# DSS_DSI0_DSI_TOP_VBUSP_CFG_DSI_0_DSI register map
Vendor: Texas Instruments
Peripheral module from a debugger description file (folder J721S2).
Registers are 32-bit, read-write, reset 0x0 unless marked. A register's access mark holds for its fields unless they carry their own. Offsets are as the file gives them; lines under a group give offsets from that group; [hi:lo] are bit positions; {n}, {i} and the like mark numbered series; 'fields as' and 'values as' point back to an identical list; <NAME> marks a mode.

## DSS_DSI0_DSI_TOP_VBUSP_CFG_DSI_0_DSI (part 1 of 2)
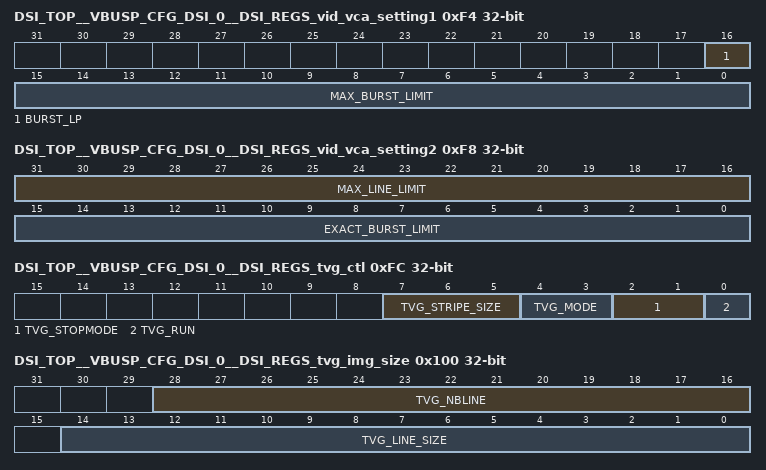
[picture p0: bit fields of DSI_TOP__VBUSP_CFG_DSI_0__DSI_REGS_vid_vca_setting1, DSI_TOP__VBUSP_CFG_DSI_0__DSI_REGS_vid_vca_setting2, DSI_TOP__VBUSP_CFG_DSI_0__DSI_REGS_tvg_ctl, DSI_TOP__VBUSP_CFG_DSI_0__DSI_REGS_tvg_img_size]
0xF4 DSI_TOP__VBUSP_CFG_DSI_0__DSI_REGS_vid_vca_setting1 — VCA control register 1
  [16] BURST_LP — BURST_LP: after an active line, the system can switch in LP [1] or should complete the line with NULL packet [0]
  [15:0] MAX_BURST_LIMIT — MAX_BURST_LIMIT: size of the 'biggest' burst packet [packet that fits after RGB in burst mode]
0xF8 DSI_TOP__VBUSP_CFG_DSI_0__DSI_REGS_vid_vca_setting2 — VCA control register 2
  [31:16] MAX_LINE_LIMIT — MAX_LINE_LIMIT: maximum size of the line packet [packet that fits in blanking line]
  [15:0] EXACT_BURST_LIMIT — EXACT_BURST_LIMIT: exact maximum size of the burst packet [packet that fits after RGB in burst mode]
0xFC DSI_TOP__VBUSP_CFG_DSI_0__DSI_REGS_tvg_ctl — Main control of the TVG
  [7:5] TVG_STRIPE_SIZE — TVG_STRIPE_SIZE: size of the stripe [in pixels] - defined by 2^reg_tvg_stripe_size
  [4:3] TVG_MODE — TVG_MODE: TVG display mode : 00 : single color ; 01 : reserved ; 10 : vertical stripes ; 11 horizontal stripes
  [2:1] TVG_STOPMODE — TVG_STOPMODE: stop mode: 00: at end of frame, 01: at end of line, 1x: immediate
  [0] TVG_RUN — TVG_RUN: start/stop of the TVG
0x100 DSI_TOP__VBUSP_CFG_DSI_0__DSI_REGS_tvg_img_size — TVG Generated image size
  [28:16] TVG_NBLINE — TVG_NBLINE: Number of lines per frame
  [14:0] TVG_LINE_SIZE — TVG_LINE_SIZE: Number of bytes per line
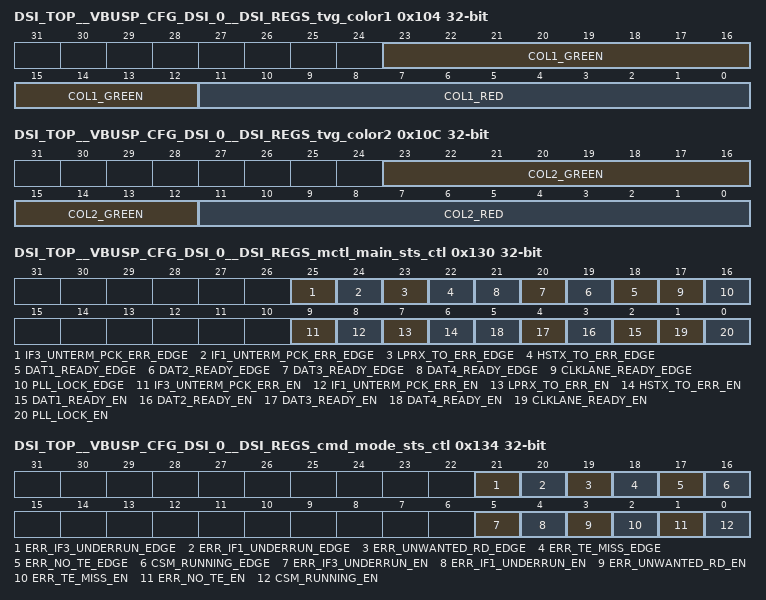
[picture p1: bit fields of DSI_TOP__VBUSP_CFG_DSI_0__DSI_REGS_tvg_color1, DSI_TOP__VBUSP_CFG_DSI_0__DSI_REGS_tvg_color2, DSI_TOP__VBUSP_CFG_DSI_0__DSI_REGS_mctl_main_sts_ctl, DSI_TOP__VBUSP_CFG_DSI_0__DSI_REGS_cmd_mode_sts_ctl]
0x104 DSI_TOP__VBUSP_CFG_DSI_0__DSI_REGS_tvg_color1 — Color 1 of the dummy frame G, R
  [23:12] COL1_GREEN — COL1_GREEN: green component of the color 1
  [11:0] COL1_RED — COL1_RED: red component of the color 1
0x108 DSI_TOP__VBUSP_CFG_DSI_0__DSI_REGS_tvg_color1_bis — Color 1 of the dummy frame , B
  [11:0] COL1_BLUE — COL1_BLUE: blue component of the color 1
0x10C DSI_TOP__VBUSP_CFG_DSI_0__DSI_REGS_tvg_color2 — Color 2 of the dummy frame, G, R
  [23:12] COL2_GREEN — COL2_GREEN: green component of the color 2
  [11:0] COL2_RED — COL2_RED: red component of the color 2
0x110 DSI_TOP__VBUSP_CFG_DSI_0__DSI_REGS_tvg_color2_bis — Color 2 of the dummy frame, B
  [11:0] COL2_BLUE — COL2_BLUE: blue component of the color 2
0x114 DSI_TOP__VBUSP_CFG_DSI_0__DSI_REGS_tvg_sts ro — TVG status register
  [0] TVG_RUNNING — TVG_RUNNING: status of the TVG
0x130 DSI_TOP__VBUSP_CFG_DSI_0__DSI_REGS_mctl_main_sts_ctl — Controls the enabling and edge detection of main ctrl status bits EDGE = 0 captures the rising edge of the event, EDGE= 1 captures falling edge.
  [25] IF3_UNTERM_PCK_ERR_EDGE — IF3_UNTERM_PCK_ERR_EDGE: edge detection of if3_unterm_pck_err
  [24] IF1_UNTERM_PCK_ERR_EDGE — IF1_UNTERM_PCK_ERR_EDGE: edge detection of if1_unterm_pck_err
  [23] LPRX_TO_ERR_EDGE — LPRX_TO_ERR_EDGE: edge detection of LP_RX time-out error
  [22] HSTX_TO_ERR_EDGE — HSTX_TO_ERR_EDGE: edge detection of HS_TX time-out error
  [n+17] DAT{n}_READY_EDGE (n=1..4) — DAT{n}_READY_EDGE: edge detection of dat{n}_ready
  [17] CLKLANE_READY_EDGE — CLKLANE_READY_EDGE: edge detection of clklane_ready
  [16] PLL_LOCK_EDGE — PLL_LOCK_EDGE: edge detection of PLL lock
  [9] IF3_UNTERM_PCK_ERR_EN — IF3_UNTERM_PCK_ERR_EN: enables if3_unterm_pck_err
  [8] IF1_UNTERM_PCK_ERR_EN — IF1_UNTERM_PCK_ERR_EN: enables if1_unterm_pck_err
  [7] LPRX_TO_ERR_EN — LPRX_TO_ERR_EN: enables lprx_to_err
  [6] HSTX_TO_ERR_EN — HSTX_TO_ERR_EN: enables hstx_to_err
  [n+1] DAT{n}_READY_EN (n=1..4) — DAT{n}_READY_EN: enables dat{n}_ready
  [1] CLKLANE_READY_EN — CLKLANE_READY_EN: enables clklane_ready
  [0] PLL_LOCK_EN — PLL_LOCK_EN: enables PLL lock
0x134 DSI_TOP__VBUSP_CFG_DSI_0__DSI_REGS_cmd_mode_sts_ctl — Controls the enabling and edge detection of command status bits EDGE = 0 captures the rising edge of the event, EDGE= 1 captures falling edge.
  [21] ERR_IF3_UNDERRUN_EDGE — ERR_IF3_UNDERRUN_EDGE: edge detection of err_IF3_underrun
  [20] ERR_IF1_UNDERRUN_EDGE — ERR_IF1_UNDERRUN_EDGE: edge detection of err_IF1_underrun
  [19] ERR_UNWANTED_RD_EDGE — ERR_UNWANTED_RD_EDGE: edge detection of err_unwanted_rd
  [18] ERR_TE_MISS_EDGE — ERR_TE_MISS_EDGE: edge detection of err_te_miss
  [17] ERR_NO_TE_EDGE — ERR_NO_TE_EDGE: edge detection of err_no_te
  [16] CSM_RUNNING_EDGE — CSM_RUNNING_EDGE: edge detection of CSM running
  [5] ERR_IF3_UNDERRUN_EN — ERR_IF3_UNDERRUN_EN: enables err_IF3_underrun
  [4] ERR_IF1_UNDERRUN_EN — ERR_IF1_UNDERRUN_EN: enables err_IF1_underrun
  [3] ERR_UNWANTED_RD_EN — ERR_UNWANTED_RD_EN: enables err_unwanted_rd
  [2] ERR_TE_MISS_EN — ERR_TE_MISS_EN: enables err_te_miss
  [1] ERR_NO_TE_EN — ERR_NO_TE_EN: enables err_no_te
  [0] CSM_RUNNING_EN — CSM_RUNNING_EN: enables signaling of CSM running
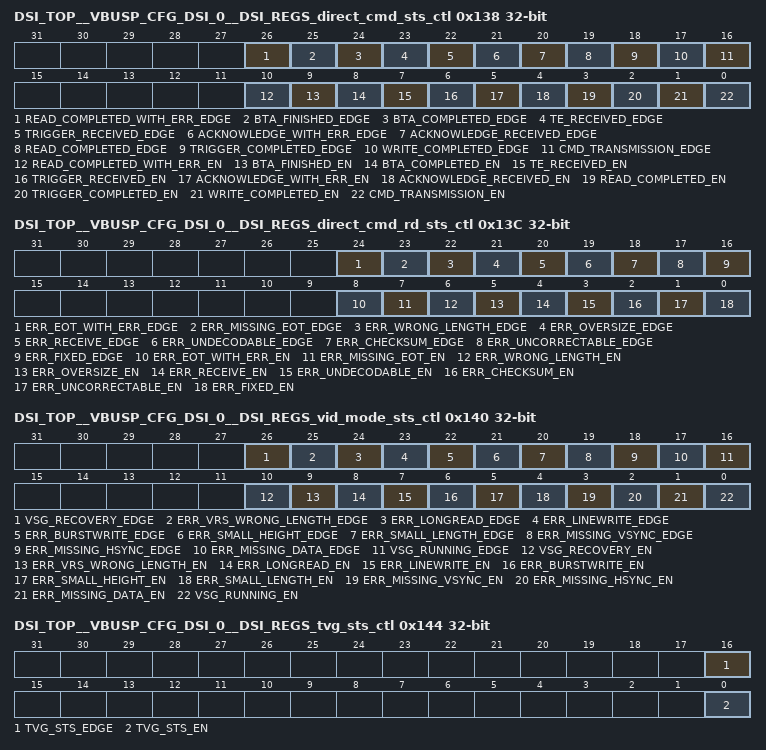
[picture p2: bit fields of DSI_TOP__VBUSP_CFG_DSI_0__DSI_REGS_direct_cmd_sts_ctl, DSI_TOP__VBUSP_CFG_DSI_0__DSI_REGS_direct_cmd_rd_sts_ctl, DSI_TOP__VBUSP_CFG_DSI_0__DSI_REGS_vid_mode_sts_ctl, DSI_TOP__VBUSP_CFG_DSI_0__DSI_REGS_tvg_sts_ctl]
0x138 DSI_TOP__VBUSP_CFG_DSI_0__DSI_REGS_direct_cmd_sts_ctl — Controls the enabling and edge detection of Direct Command status bits
  [26] READ_COMPLETED_WITH_ERR_EDGE — READ_COMPLETED_WITH_ERR_EDGE: edge detection of read detection completed with errors
  [25] BTA_FINISHED_EDGE — BTA_FINISHED_EDGE: edge detection of BTA completion detection
  [24] BTA_COMPLETED_EDGE — BTA_COMPLETED_EDGE: edge detection of BTA request completed
  [23] TE_RECEIVED_EDGE — TE_RECEIVED_EDGE: edge detection of TE received
  [22] TRIGGER_RECEIVED_EDGE — TRIGGER_RECEIVED_EDGE: edge detection of trigger
  [21] ACKNOWLEDGE_WITH_ERR_EDGE — ACKNOWLEDGE_WITH_ERR_EDGE: edge detection of acknowledge with error
  [20] ACKNOWLEDGE_RECEIVED_EDGE — ACKNOWLEDGE_RECEIVED_EDGE: edge detection of acknowledge
  [19] READ_COMPLETED_EDGE — READ_COMPLETED_EDGE: edge detection of read request completed
  [18] TRIGGER_COMPLETED_EDGE — TRIGGER_COMPLETED_EDGE: edge detection of trigger request completed
  [17] WRITE_COMPLETED_EDGE — WRITE_COMPLETED_EDGE: edge detection of detection of write request completed
  [16] CMD_TRANSMISSION_EDGE — CMD_TRANSMISSION_EDGE: edge detection of cmd_transmission
  [10] READ_COMPLETED_WITH_ERR_EN — READ_COMPLETED_WITH_ERR_EN: enables detection of read completed with errors
  [9] BTA_FINISHED_EN — BTA_FINISHED_EN: enables BTA completion detection
  [8] BTA_COMPLETED_EN — BTA_COMPLETED_EN: enables BTA request completed
  [7] TE_RECEIVED_EN — TE_RECEIVED_EN: enables TE received
  [6] TRIGGER_RECEIVED_EN — TRIGGER_RECEIVED_EN: enables trigger
  [5] ACKNOWLEDGE_WITH_ERR_EN — ACKNOWLEDGE_WITH_ERR_EN: enables acknowledge with error
  [4] ACKNOWLEDGE_RECEIVED_EN — ACKNOWLEDGE_RECEIVED_EN: enables acknowledge
  [3] READ_COMPLETED_EN — READ_COMPLETED_EN: enables read request completed
  [2] TRIGGER_COMPLETED_EN — TRIGGER_COMPLETED_EN: enables trigger_completed
  [1] WRITE_COMPLETED_EN — WRITE_COMPLETED_EN: enables write_completed
  [0] CMD_TRANSMISSION_EN — CMD_TRANSMISSION_EN: enables detection of cmd_transmission
0x13C DSI_TOP__VBUSP_CFG_DSI_0__DSI_REGS_direct_cmd_rd_sts_ctl — Controls the enabling and edge detection of read commands error
  [24] ERR_EOT_WITH_ERR_EDGE — ERR_EOT_WITH_ERR_EDGE: edge detection of err_eot_with_err
  [23] ERR_MISSING_EOT_EDGE — ERR_MISSING_EOT_EDGE: edge detection of err_missing_eot
  [22] ERR_WRONG_LENGTH_EDGE — ERR_WRONG_LENGTH_EDGE: edge detection of err_wrong_length
  [21] ERR_OVERSIZE_EDGE — ERR_OVERSIZE_EDGE: edge detection of err_oversize
  [20] ERR_RECEIVE_EDGE — ERR_RECEIVE_EDGE: edge detection of err_receive
  [19] ERR_UNDECODABLE_EDGE — ERR_UNDECODABLE_EDGE: edge detection of err_undecodable
  [18] ERR_CHECKSUM_EDGE — ERR_CHECKSUM_EDGE: edge detection of err_checksum
  [17] ERR_UNCORRECTABLE_EDGE — ERR_UNCORRECTABLE_EDGE: edge detection of err_uncorrectable
  [16] ERR_FIXED_EDGE — ERR_FIXED_EDGE: edge detection of err_fixed
  [8] ERR_EOT_WITH_ERR_EN — ERR_EOT_WITH_ERR_EN: enables err_eot_with_err
  [7] ERR_MISSING_EOT_EN — ERR_MISSING_EOT_EN: enables err_missing_eot
  [6] ERR_WRONG_LENGTH_EN — ERR_WRONG_LENGTH_EN: enables err_wrong_length
  [5] ERR_OVERSIZE_EN — ERR_OVERSIZE_EN: enables err_oversize
  [4] ERR_RECEIVE_EN — ERR_RECEIVE_EN: enables err_receive
  [3] ERR_UNDECODABLE_EN — ERR_UNDECODABLE_EN: enables err_undecodable
  [2] ERR_CHECKSUM_EN — ERR_CHECKSUM_EN: enables err_checksum
  [1] ERR_UNCORRECTABLE_EN — ERR_UNCORRECTABLE_EN: enables err_uncorrectable
  [0] ERR_FIXED_EN — ERR_FIXED_EN: enables err_fixed
0x140 DSI_TOP__VBUSP_CFG_DSI_0__DSI_REGS_vid_mode_sts_ctl — Control the enabling and edge detection of VSG status bits
  [26] VSG_RECOVERY_EDGE — VSG_RECOVERY_EDGE: edge detection of vsg_recovery
  [25] ERR_VRS_WRONG_LENGTH_EDGE — ERR_VRS_WRONG_LENGTH_EDGE: edge detection of err_vrs_wrong_length
  [24] ERR_LONGREAD_EDGE — ERR_LONGREAD_EDGE: edge detection of err_longread
  [23] ERR_LINEWRITE_EDGE — ERR_LINEWRITE_EDGE: edge detection of err_line_write
  [22] ERR_BURSTWRITE_EDGE — ERR_BURSTWRITE_EDGE: edge detection of err_burst_write
  [21] ERR_SMALL_HEIGHT_EDGE — ERR_SMALL_HEIGHT_EDGE: edge detection of unaligned line number
  [20] ERR_SMALL_LENGTH_EDGE — ERR_SMALL_LENGTH_EDGE: edge detection of unaligned size
  [19] ERR_MISSING_VSYNC_EDGE — ERR_MISSING_VSYNC_EDGE: edge detection of detection of missing VSYNC
  [18] ERR_MISSING_HSYNC_EDGE — ERR_MISSING_HSYNC_EDGE: edge detection of detection of missing HSYNC
  [17] ERR_MISSING_DATA_EDGE — ERR_MISSING_DATA_EDGE: edge detection of data miss detection
  [16] VSG_RUNNING_EDGE — VSG_RUNNING_EDGE: edge detection of VSG status observation
  [10] VSG_RECOVERY_EN — VSG_RECOVERY_EN: enables vsg_recovery
  [9] ERR_VRS_WRONG_LENGTH_EN — ERR_VRS_WRONG_LENGTH_EN: enables err_vrs_wrong_length
  [8] ERR_LONGREAD_EN — ERR_LONGREAD_EN: enables err_longread
  [7] ERR_LINEWRITE_EN — ERR_LINEWRITE_EN: enables err_line_write
  [6] ERR_BURSTWRITE_EN — ERR_BURSTWRITE_EN: enables err_burst_write
  [5] ERR_SMALL_HEIGHT_EN — ERR_SMALL_HEIGHT_EN: enables detection of unaligned line number
  [4] ERR_SMALL_LENGTH_EN — ERR_SMALL_LENGTH_EN: enables detection of unaligned size
  [3] ERR_MISSING_VSYNC_EN — ERR_MISSING_VSYNC_EN: enables detection of missing VSYNC
  [2] ERR_MISSING_HSYNC_EN — ERR_MISSING_HSYNC_EN: enables detection of missing HSYNC
  [1] ERR_MISSING_DATA_EN — ERR_MISSING_DATA_EN: enables data miss detection
  [0] VSG_RUNNING_EN — VSG_RUNNING_EN: enables VSG status observation
0x144 DSI_TOP__VBUSP_CFG_DSI_0__DSI_REGS_tvg_sts_ctl — Control the enabling and edge detection of TVG status bits
  [16] TVG_STS_EDGE — TVG_STS_EDGE: edge detection of TVG status observation
  [0] TVG_STS_EN — TVG_STS_EN: enables TVG status observation
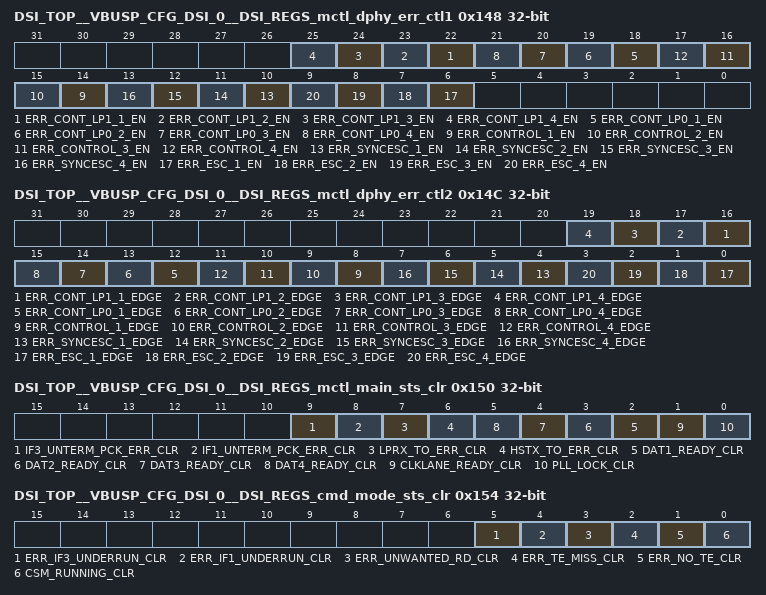
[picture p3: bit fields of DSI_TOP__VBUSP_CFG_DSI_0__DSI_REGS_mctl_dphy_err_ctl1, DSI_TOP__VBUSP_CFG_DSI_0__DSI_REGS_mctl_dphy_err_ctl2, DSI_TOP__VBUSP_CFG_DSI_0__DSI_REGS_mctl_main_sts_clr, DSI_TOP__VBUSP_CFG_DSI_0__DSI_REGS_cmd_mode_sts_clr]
0x148 DSI_TOP__VBUSP_CFG_DSI_0__DSI_REGS_mctl_dphy_err_ctl1 — Controls the enabling and edge detection of the DPHY errors
  [n+21] ERR_CONT_LP1_{n}_EN (n=1..4), [n+17] ERR_CONT_LP0_{n}_EN (n=1..4), [n+13] ERR_CONTROL_{n}_EN (n=1..4), [n+9] ERR_SYNCESC_{n}_EN (n=1..4), [n+5] ERR_ESC_{n}_EN (n=1..4)
0x14C DSI_TOP__VBUSP_CFG_DSI_0__DSI_REGS_mctl_dphy_err_ctl2 — Controls he enabling and edge detection of the DPHY errors
  [n+15] ERR_CONT_LP1_{n}_EDGE (n=1..4), [n+11] ERR_CONT_LP0_{n}_EDGE (n=1..4), [n+7] ERR_CONTROL_{n}_EDGE (n=1..4), [n+3] ERR_SYNCESC_{n}_EDGE (n=1..4), [n-1] ERR_ESC_{n}_EDGE (n=1..4)
0x150 DSI_TOP__VBUSP_CFG_DSI_0__DSI_REGS_mctl_main_sts_clr wo — Main control status register clear function. These bits are spread across different register banks. The exact use of the set and reset is described in the section : Error and status bits. Write '1' to clear
  [9] IF3_UNTERM_PCK_ERR_CLR — IF3_UNTERM_PCK_ERR_CLR: clears if3_unterm_pck_err
  [8] IF1_UNTERM_PCK_ERR_CLR — IF1_UNTERM_PCK_ERR_CLR: clears if1_unterm_pck_err
  [7] LPRX_TO_ERR_CLR — LPRX_TO_ERR_CLR: clears lprx_to_err
  [6] HSTX_TO_ERR_CLR — HSTX_TO_ERR_CLR: clears hstx_to_err
  [n+1] DAT{n}_READY_CLR (n=1..4) — DAT{n}_READY_CLR: clears dat{n}_ready
  [1] CLKLANE_READY_CLR — CLKLANE_READY_CLR: clears clklane_ready
  [0] PLL_LOCK_CLR — PLL_LOCK_CLR: clears PLL lock
0x154 DSI_TOP__VBUSP_CFG_DSI_0__DSI_REGS_cmd_mode_sts_clr access per field — Command status register clear function. Write '1' to clear
  [5] ERR_IF3_UNDERRUN_CLR ro — ERR_IF3_UNDERRUN_CLR: clears err_IF3_underrun
  [4] ERR_IF1_UNDERRUN_CLR wo — ERR_IF1_UNDERRUN_CLR: clears err_IF1_underrun
  [3] ERR_UNWANTED_RD_CLR wo — ERR_UNWANTED_RD_CLR: clears err_unwanted_rd
  [2] ERR_TE_MISS_CLR wo — ERR_TE_MISS_CLR: clears err_te_miss
  [1] ERR_NO_TE_CLR wo — ERR_NO_TE_CLR: clears err_no_te
  [0] CSM_RUNNING_CLR wo — CSM_RUNNING_CLR: clears CSM running bit
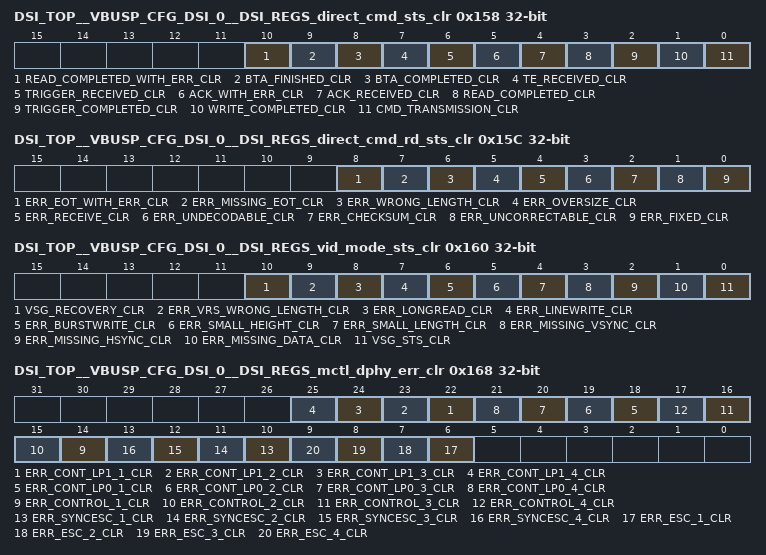
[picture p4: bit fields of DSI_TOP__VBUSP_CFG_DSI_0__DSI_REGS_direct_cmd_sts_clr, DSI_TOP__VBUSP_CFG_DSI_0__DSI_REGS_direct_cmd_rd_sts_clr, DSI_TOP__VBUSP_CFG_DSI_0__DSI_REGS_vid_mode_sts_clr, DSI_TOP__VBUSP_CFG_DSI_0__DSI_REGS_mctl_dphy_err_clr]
0x158 DSI_TOP__VBUSP_CFG_DSI_0__DSI_REGS_direct_cmd_sts_clr wo — Direct command status register clear function. Write '1' to clear
  [10] READ_COMPLETED_WITH_ERR_CLR — READ_COMPLETED_WITH_ERR_CLR: clears detection of read completed with errors
  [9] BTA_FINISHED_CLR — BTA_FINISHED_CLR: clears BTA completion detection
  [8] BTA_COMPLETED_CLR — BTA_COMPLETED_CLR: clears BTA request completed
  [7] TE_RECEIVED_CLR — TE_RECEIVED_CLR: clears TE received
  [6] TRIGGER_RECEIVED_CLR — TRIGGER_RECEIVED_CLR: clears trigger
  [5] ACK_WITH_ERR_CLR — ACKNOWLEDGE_WITH_ERR_CLR: clears acknowledge with errors
  [4] ACK_RECEIVED_CLR — ACKNOWLEDGE_RECEIVED_CLR: clears acknowledge
  [3] READ_COMPLETED_CLR — READ_COMPLETED_CLR: clears read request completed
  [2] TRIGGER_COMPLETED_CLR — TRIGGER_COMPLETED_CLR: clears trigger request completed
  [1] WRITE_COMPLETED_CLR — WRITE_COMPLETED_CLR: clears detection of write request completed
  [0] CMD_TRANSMISSION_CLR — CMD_TRANSMISSION_CLR: clears cmd_transmission
0x15C DSI_TOP__VBUSP_CFG_DSI_0__DSI_REGS_direct_cmd_rd_sts_clr wo — Direct command read status register clear function. Write '1' to clear
  [8] ERR_EOT_WITH_ERR_CLR — ERR_EOT_WITH_ERR_CLR: clears err_eot_with_err
  [7] ERR_MISSING_EOT_CLR — ERR_MISSING_EOT_CLR: clears err_missing_eot
  [6] ERR_WRONG_LENGTH_CLR — ERR_WRONG_LENGTH_CLR: clears err_wrong_length
  [5] ERR_OVERSIZE_CLR — ERR_OVERSIZE_CLR: clears err_oversize
  [4] ERR_RECEIVE_CLR — ERR_RECEIVE_CLR: clears err_receive
  [3] ERR_UNDECODABLE_CLR — ERR_UNDECODABLE_CLR: clears err_undecodable
  [2] ERR_CHECKSUM_CLR — ERR_CHECKSUM_CLR: clears err_checksum
  [1] ERR_UNCORRECTABLE_CLR — ERR_UNCORRECTABLE_CLR: clears err_uncorrectable
  [0] ERR_FIXED_CLR — ERR_FIXED_CLR: clears err_fixed
0x160 DSI_TOP__VBUSP_CFG_DSI_0__DSI_REGS_vid_mode_sts_clr wo — VSG status register clear function
  [10] VSG_RECOVERY_CLR — VSG_RECOVERY_CLR: clears the bit vsg_recovery
  [9] ERR_VRS_WRONG_LENGTH_CLR — ERR_VRS_WRONG_LENGTH_CLR: clears the bit err_vid_wrong_length
  [8] ERR_LONGREAD_CLR — ERR_LONGREAD_CLR: clears err_longread
  [7] ERR_LINEWRITE_CLR — ERR_LINEWRITE_CLR: clears err_linewrite
  [6] ERR_BURSTWRITE_CLR — ERR_BURSTWRITE_CLR: clears err_burstwrite
  [5] ERR_SMALL_HEIGHT_CLR — ERR_SMALL_HEIGHT_CLR: clears unaligned line number
  [4] ERR_SMALL_LENGTH_CLR — ERR_SMALL_LENGTH_CLR: clears analigned size
  [3] ERR_MISSING_VSYNC_CLR — ERR_MISSING_VSYNC_CLR: clears missing VSYNC
  [2] ERR_MISSING_HSYNC_CLR — ERR_MISSING_HSYNC_CLR: clears missing HSYNC
  [1] ERR_MISSING_DATA_CLR — ERR_MISSING_DATA_CLR: clears data miss
  [0] VSG_STS_CLR — VSG_STS_CLR: clears VSG status
0x164 DSI_TOP__VBUSP_CFG_DSI_0__DSI_REGS_tg_sts_clr wo — TVG status register clear function. Write '1' to clear
  [0] TVG_STS_CLR — TVG_STS_CLR: clears TVG status observation
0x168 DSI_TOP__VBUSP_CFG_DSI_0__DSI_REGS_mctl_dphy_err_clr wo — D_PHY lanes output register clear function. Write '1' to clear
  [n+21] ERR_CONT_LP1_{n}_CLR (n=1..4), [n+17] ERR_CONT_LP0_{n}_CLR (n=1..4), [n+13] ERR_CONTROL_{n}_CLR (n=1..4), [n+9] ERR_SYNCESC_{n}_CLR (n=1..4), [n+5] ERR_ESC_{n}_CLR (n=1..4)
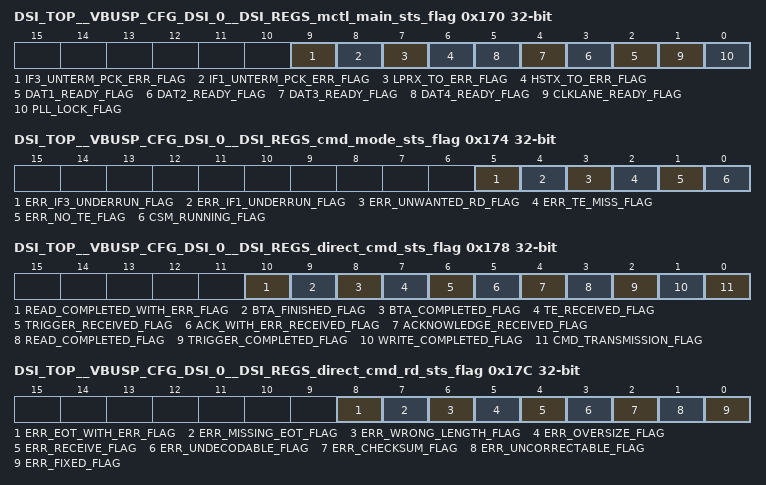
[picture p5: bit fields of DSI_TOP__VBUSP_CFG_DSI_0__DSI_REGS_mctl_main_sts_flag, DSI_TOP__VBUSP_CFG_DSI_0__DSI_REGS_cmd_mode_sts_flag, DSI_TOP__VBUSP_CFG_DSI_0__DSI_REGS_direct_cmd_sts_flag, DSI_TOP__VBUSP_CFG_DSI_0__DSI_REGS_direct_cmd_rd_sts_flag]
0x170 DSI_TOP__VBUSP_CFG_DSI_0__DSI_REGS_mctl_main_sts_flag ro — Main control status Flag registers. The use of these registers is related to status and error bits management (and interrupt too). These bits are spread across different register banks. The exact use of the flag bit is described in the section : Error and status bits.
  [9] IF3_UNTERM_PCK_ERR_FLAG — IF3_UNTERM_PCK_ERR_FLAG: flags if3_unterm_pck_err
  [8] IF1_UNTERM_PCK_ERR_FLAG — IF1_UNTERM_PCK_ERR_FLAG: flags if1_unterm_pck_err
  [7] LPRX_TO_ERR_FLAG — LPRX_TO_ERR_FLAG: flags lprx_to_err
  [6] HSTX_TO_ERR_FLAG — HSTX_TO_ERR_FLAG: flags hstx_to_err
  [n+1] DAT{n}_READY_FLAG (n=1..4) — DAT{n}_READY_FLAG: flags dat{n}_ready
  [1] CLKLANE_READY_FLAG — CLKLANE_READY_FLAG: flags clklane_ready
  [0] PLL_LOCK_FLAG — PLL_LOCK_FLAG: flags PLL lock
0x174 DSI_TOP__VBUSP_CFG_DSI_0__DSI_REGS_cmd_mode_sts_flag ro — Command Mode status
  [5] ERR_IF3_UNDERRUN_FLAG — ERR_IF3_UNDERRUN_FLAG: flags err_IF3_underrun
  [4] ERR_IF1_UNDERRUN_FLAG — ERR_IF1_UNDERRUN_FLAG: flags err_IF1_underrun
  [3] ERR_UNWANTED_RD_FLAG — ERR_UNWANTED_RD_FLAG: flags fixed_err
  [2] ERR_TE_MISS_FLAG — ERR_TE_MISS_FLAG: flags err_te_miss
  [1] ERR_NO_TE_FLAG — ERR_NO_TE_FLAG: flags err_no_te
  [0] CSM_RUNNING_FLAG — CSM_RUNNING_FLAG: flags remaining_err
0x178 DSI_TOP__VBUSP_CFG_DSI_0__DSI_REGS_direct_cmd_sts_flag ro — Direct command mode status
  [10] READ_COMPLETED_WITH_ERR_FLAG — READ_COMPLETED_WITH_ERR_FLAG: flags detection of read completed with errors
  [9] BTA_FINISHED_FLAG — BTA_FINISHED_FLAG: flags BTA completion detection
  [8] BTA_COMPLETED_FLAG — BTA_COMPLETED_FLAG: flags BTA request completed
  [7] TE_RECEIVED_FLAG — TE_RECEIVED_FLAG: flags TE received
  [6] TRIGGER_RECEIVED_FLAG — TRIGGER_RECEIVED_FLAG: flags trigger
  [5] ACK_WITH_ERR_RECEIVED_FLAG — ACK_WITH_ERR_RECEIVED_FLAG: flag acknowledge with error detection
  [4] ACKNOWLEDGE_RECEIVED_FLAG — ACKNOWLEDGE_RECEIVED_FLAG: flags acknowledge
  [3] READ_COMPLETED_FLAG — READ_COMPLETED_FLAG: flags read request completed
  [2] TRIGGER_COMPLETED_FLAG — TRIGGER_COMPLETED_FLAG: flags trigger request completed
  [1] WRITE_COMPLETED_FLAG — WRITE_COMPLETED_FLAG: flags detection of write request completed
  [0] CMD_TRANSMISSION_FLAG — CMD_TRANSMISSION_FLAG: flags cmd_transmission
0x17C DSI_TOP__VBUSP_CFG_DSI_0__DSI_REGS_direct_cmd_rd_sts_flag ro — Direct command read status bits
  [8] ERR_EOT_WITH_ERR_FLAG — ERR_EOT_WITH_ERR_FLAG: flags err_eot_with_err
  [7] ERR_MISSING_EOT_FLAG — ERR_MISSING_EOT_FLAG: flags err_missing_eot
  [6] ERR_WRONG_LENGTH_FLAG — ERR_WRONG_LENGTH_FLAG: flags err_wrong_length
  [5] ERR_OVERSIZE_FLAG — ERR_OVERSIZE_FLAG: flags err_oversize
  [4] ERR_RECEIVE_FLAG — ERR_RECEIVE_FLAG: flags err_receive
  [3] ERR_UNDECODABLE_FLAG — ERR_UNDECODABLE_FLAG: flags err_undecodable
  [2] ERR_CHECKSUM_FLAG — ERR_CHECKSUM_FLAG: flags err_checksum
  [1] ERR_UNCORRECTABLE_FLAG — ERR_UNCORRECTABLE_FLAG: flags err_uncorrectable
  [0] ERR_FIXED_FLAG — ERR_FIXED_FLAG: flags err_fixed
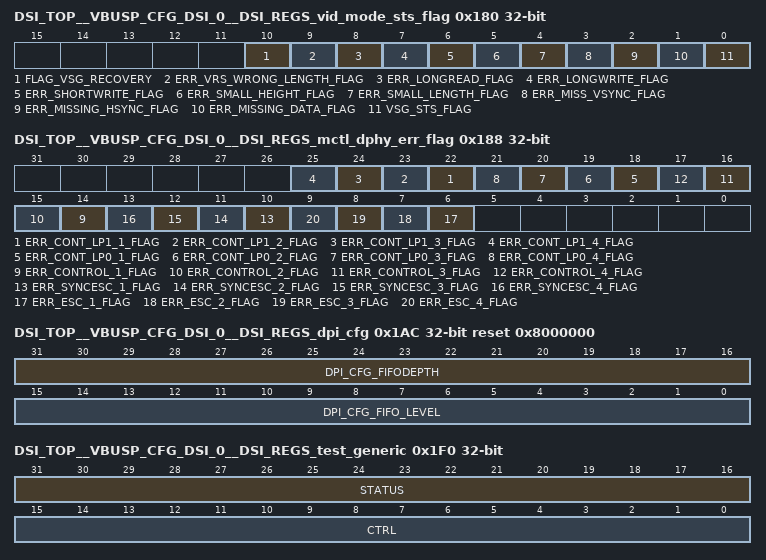
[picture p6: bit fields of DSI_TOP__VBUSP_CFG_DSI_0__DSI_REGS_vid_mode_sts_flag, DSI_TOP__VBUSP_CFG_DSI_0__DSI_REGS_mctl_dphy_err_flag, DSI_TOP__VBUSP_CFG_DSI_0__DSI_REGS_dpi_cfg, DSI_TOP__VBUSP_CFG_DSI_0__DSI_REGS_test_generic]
0x180 DSI_TOP__VBUSP_CFG_DSI_0__DSI_REGS_vid_mode_sts_flag ro — Video Mode status flag
  [10] FLAG_VSG_RECOVERY — FLAG_VSG_RECOVERY: lags vsg_recovery
  [9] ERR_VRS_WRONG_LENGTH_FLAG — ERR_VRS_WRONG_LENGTH_FLAG: flags err_vrs_wrong_length
  [8] ERR_LONGREAD_FLAG — ERR_LONGREAD_FLAG: flags err_longread
  [7] ERR_LONGWRITE_FLAG — ERR_LONGWRITE_FLAG: flags err_longwrite
  [6] ERR_SHORTWRITE_FLAG — ERR_SHORTWRITE_FLAG: flags err_shortwrite
  [5] ERR_SMALL_HEIGHT_FLAG — ERR_SMALL_HEIGHT_FLAG: flags the detection of unaligned line number
  [4] ERR_SMALL_LENGTH_FLAG — ERR_SMALL_LENGTH_FLAG: flags the detection of unaligned size
  [3] ERR_MISS_VSYNC_FLAG — ERR_MISS_VSYNC_FLAG: flags missing VSYNC
  [2] ERR_MISSING_HSYNC_FLAG — ERR_MISSING_HSYNC_FLAG: flags missing HSYNC
  [1] ERR_MISSING_DATA_FLAG — ERR_MISSING_DATA_FLAG: flags data miss
  [0] VSG_STS_FLAG — VSG_STS_FLAG: flags VSG status
0x184 DSI_TOP__VBUSP_CFG_DSI_0__DSI_REGS_tg_sts_flag ro — TVG status Flags
  [0] TVG_STS_FLAG — TVG_STS_FLAG: Indicates TVG status observation
0x188 DSI_TOP__VBUSP_CFG_DSI_0__DSI_REGS_mctl_dphy_err_flag ro — Errors output from D_PHY lanes - flags error bit
  [n+21] ERR_CONT_LP1_{n}_FLAG (n=1..4), [n+17] ERR_CONT_LP0_{n}_FLAG (n=1..4), [n+13] ERR_CONTROL_{n}_FLAG (n=1..4), [n+9] ERR_SYNCESC_{n}_FLAG (n=1..4), [n+5] ERR_ESC_{n}_FLAG (n=1..4)
0x1A0 DSI_TOP__VBUSP_CFG_DSI_0__DSI_REGS_dpi_irq_en — DPI interrupt enable
  [0] PIXEL_BUF_OVERFLOW_IRQ_EN — Enable DPI FIFO Overflow interrupt
0x1A4 DSI_TOP__VBUSP_CFG_DSI_0__DSI_REGS_dpi_irq_clr wo — DPI interrupt clear register
  [0] PIXEL_BUF_OVERFLOW_IRQ_CLR — Clear DPI FIFO Overflow interrupt
0x1A8 DSI_TOP__VBUSP_CFG_DSI_0__DSI_REGS_dpi_irq_sts ro — DPI interrupt status
  [0] PIXEL_BUF_OVERFLOW_STS — Status of DPI FIFO Overflow interrupt
0x1AC DSI_TOP__VBUSP_CFG_DSI_0__DSI_REGS_dpi_cfg ro reset 0x8000000 — DPI interface configuration information
  [31:16] DPI_CFG_FIFODEPTH — DPI FIFO depth - configuration paramter
  [15:0] DPI_CFG_FIFO_LEVEL — DPI FIFO fill level - can be read mid-line for debug purposes, to allow adjustment of settings
0x1F0 DSI_TOP__VBUSP_CFG_DSI_0__DSI_REGS_test_generic access per field — Generic test control and status register
  [31:16] STATUS ro — Test status - Value of test_generic_status input
  [15:0] CTRL rw — Test control - Drives test_generic_ctrl output
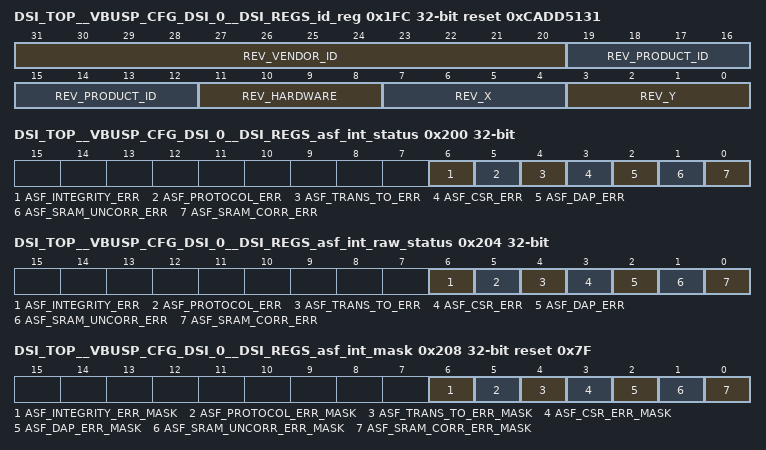
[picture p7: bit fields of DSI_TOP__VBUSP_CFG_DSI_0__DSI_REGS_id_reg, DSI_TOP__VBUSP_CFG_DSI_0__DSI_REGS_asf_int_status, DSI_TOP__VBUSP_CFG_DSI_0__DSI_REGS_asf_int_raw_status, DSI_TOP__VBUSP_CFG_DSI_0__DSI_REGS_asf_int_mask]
0x1FC DSI_TOP__VBUSP_CFG_DSI_0__DSI_REGS_id_reg ro reset 0xCADD5131 — ID register for Controller
  [31:20] REV_VENDOR_ID — VENDOR_ID: IP vendor ID affected to CadenceIP [reset = 0xCAD].
  [19:12] REV_PRODUCT_ID — PRODUCT_ID: unique IP identifier within IP portfolio [reset = 0xD5].
  [11:8] REV_HARDWARE — H: Hardware revision number [reset = 0x1].
  [7:4] REV_X — X: Major revision value [reset = 0x3].
  [3:0] REV_Y — Y: Minor revision value [reset = 0x1].
0x200 DSI_TOP__VBUSP_CFG_DSI_0__DSI_REGS_asf_int_status access not given — ASF Interrupt Status Register. This register indicates the source of ASF interrupts. The corresponding bit in the mask register must be clear for a bit to be set. If any bit is set in this register the asf_int_fatal or asf_int_nonfatal signal will be asserted. Writing to either raw or masked status registers, clear both registers. For test purposes, trigger signal interrupt event by writing to the ASF interrupt status test register.
  [6] ASF_INTEGRITY_ERR — Integrity error interrupt (access R/W1TC)
  [5] ASF_PROTOCOL_ERR — Protocol error interrupt (access R/W1TC)
  [4] ASF_TRANS_TO_ERR — Transaction timeouts error interrupt (access R/W1TC)
  [3] ASF_CSR_ERR — Configuration and status registers error interrupt (access R/W1TC)
  [2] ASF_DAP_ERR — Data and address paths parity error interrupt (access R/W1TC)
  [1] ASF_SRAM_UNCORR_ERR — SRAM uncorrectable error interrupt (access R/W1TC)
  [0] ASF_SRAM_CORR_ERR — SRAM correctable error interrupt (access R/W1TC)
0x204 DSI_TOP__VBUSP_CFG_DSI_0__DSI_REGS_asf_int_raw_status access not given — ASF Interrupt Raw Status Register. A bit set in this raw register indicates a source of ASF fault in the corresponding feature. Writing to either raw or masked status registers, clear both registers. For test purposes, trigger signal interrupt event by writing to the ASF interrupt status test register.
  fields as DSI_TOP__VBUSP_CFG_DSI_0__DSI_REGS_asf_int_status
0x208 DSI_TOP__VBUSP_CFG_DSI_0__DSI_REGS_asf_int_mask access not given reset 0x7F — The ASF interrupt mask register indicating which interrupt bits in the ASF interrupt status register are masked. All bits are set at reset. Clear the individual bit to enable the corresponding interrupt.
  [6] ASF_INTEGRITY_ERR_MASK rw — Mask bit for integrity error interrupt
  [5] ASF_PROTOCOL_ERR_MASK rw — Mask bit for protocol error interrupt.
  [4] ASF_TRANS_TO_ERR_MASK rw — Mask bit for transaction timeouts error interrupt.
  [3] ASF_CSR_ERR_MASK rw — Mask bit for configuration and status registers error interrupt.
  [2] ASF_DAP_ERR_MASK rw — Mask bit for data and address paths parity error interrupt.
  [1] ASF_SRAM_UNCORR_ERR_MASK rw — Mask bit for SRAM uncorrectable error interrupt.
  [0] ASF_SRAM_CORR_ERR_MASK rw — Mask bit for SRAM correctable error interrupt.
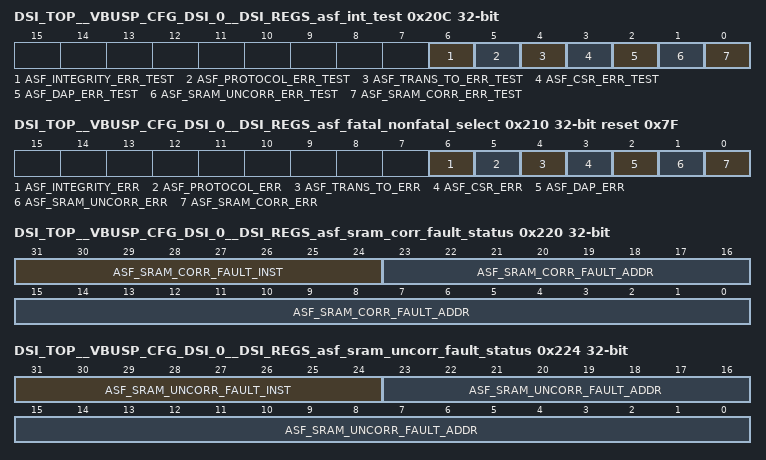
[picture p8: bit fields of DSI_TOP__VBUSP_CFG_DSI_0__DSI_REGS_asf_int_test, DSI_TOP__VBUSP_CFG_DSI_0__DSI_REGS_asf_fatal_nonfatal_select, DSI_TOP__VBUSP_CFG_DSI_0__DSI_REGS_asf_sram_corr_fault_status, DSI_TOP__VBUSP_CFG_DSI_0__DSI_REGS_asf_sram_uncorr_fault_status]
0x20C DSI_TOP__VBUSP_CFG_DSI_0__DSI_REGS_asf_int_test access not given — The ASF interrupt test register emulate hardware even. Write one to individual bit to trigger single event in (masked and raw) status registers according to mask and will generate interrupt accordingly.
  [6] ASF_INTEGRITY_ERR_TEST wo — Test bit for integrity error interrupt
  [5] ASF_PROTOCOL_ERR_TEST wo — Test bit for protocol error interrupt.
  [4] ASF_TRANS_TO_ERR_TEST wo — Test bit for transaction timeouts error interrupt.
  [3] ASF_CSR_ERR_TEST wo — Test bit for configuration and status registers error interrupt.
  [2] ASF_DAP_ERR_TEST wo — Test bit for data and address paths parity error interrupt.
  [1] ASF_SRAM_UNCORR_ERR_TEST wo — Test bit for SRAM uncorrectable error interrupt.
  [0] ASF_SRAM_CORR_ERR_TEST wo — Test bit for SRAM correctable error interrupt.
0x210 DSI_TOP__VBUSP_CFG_DSI_0__DSI_REGS_asf_fatal_nonfatal_select access not given reset 0x7F — The fatal or non-fatal interrupt register selects whether a fatal (asf_int_fatal) or non-fatal (asf_int_nonfatal) interrupt is triggered. If the bit of the event will be set to one then fatal interrupt (asf_int_fatal) will be triggered. Otherwise the non-fatal interrupt (asf_int_nonfatal) will be triggered.
  [6] ASF_INTEGRITY_ERR rw — Enable integrity error interrupt as fatal
  [5] ASF_PROTOCOL_ERR rw — Enable protocol error interrupt as fatal.
  [4] ASF_TRANS_TO_ERR rw — Enable transaction timeouts error interrupt as fatal.
  [3] ASF_CSR_ERR rw — Enable configuration and status registers error interrupt as fatal.
  [2] ASF_DAP_ERR rw — Enable data and address paths parity error interrupt as fatal.
  [1] ASF_SRAM_UNCORR_ERR rw — Enable SRAM uncorrectable error interrupt as fatal.
  [0] ASF_SRAM_CORR_ERR rw — Enable SRAM correctable error interrupt as fatal.
0x220 DSI_TOP__VBUSP_CFG_DSI_0__DSI_REGS_asf_sram_corr_fault_status ro — Status register for SRAM correctable fault. These fields are updated whenever asf_sram_corr_fault input is active.
  [31:24] ASF_SRAM_CORR_FAULT_INST — Last SRAM instance that generated fault.
  [23:0] ASF_SRAM_CORR_FAULT_ADDR — Last SRAM address that generated fault.
0x224 DSI_TOP__VBUSP_CFG_DSI_0__DSI_REGS_asf_sram_uncorr_fault_status ro — Status register for SRAM uncorrectable fault. These fields are updated whenever asf_sram_uncorr_fault input is active.
  [31:24] ASF_SRAM_UNCORR_FAULT_INST — Last SRAM instance that generated fault.
  [23:0] ASF_SRAM_UNCORR_FAULT_ADDR — Last SRAM address that generated fault.
0x228 DSI_TOP__VBUSP_CFG_DSI_0__DSI_REGS_asf_sram_fault_stats access not given — Statistics register for SRAM faults. Note that this register clears when software writes to any field.
  [15:0] ASF_SRAM_FAULT_CORR_STATS — Count of number of correctable errors if implemented. Count value will saturate at 0xffff. (access R/W1TC)
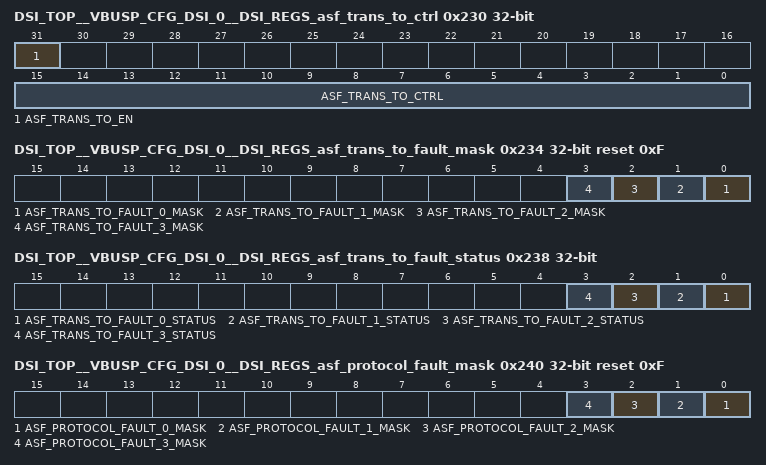
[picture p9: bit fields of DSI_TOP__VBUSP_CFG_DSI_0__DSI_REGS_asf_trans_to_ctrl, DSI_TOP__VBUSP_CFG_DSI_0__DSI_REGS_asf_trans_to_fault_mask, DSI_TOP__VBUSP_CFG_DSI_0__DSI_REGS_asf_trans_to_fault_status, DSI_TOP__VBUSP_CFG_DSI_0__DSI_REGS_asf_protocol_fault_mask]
0x230 DSI_TOP__VBUSP_CFG_DSI_0__DSI_REGS_asf_trans_to_ctrl — Control register to configure the ASF transaction timeout monitors.
  [31] ASF_TRANS_TO_EN — Enable transaction timeout monitoring.
  [15:0] ASF_TRANS_TO_CTRL — Timer value to use for transaction timeout monitor.
0x234 DSI_TOP__VBUSP_CFG_DSI_0__DSI_REGS_asf_trans_to_fault_mask reset 0xF — Control register to mask out ASF transaction timeout faults from triggering interrupts. On reset, all bits are set to mask out all sources. Clear the corresponding bit to enable the interrupt source. The width of this field is parameterisable and the bit definitions are implementation specific.
  [n] ASF_TRANS_TO_FAULT_{n}_MASK (n=0..3) — Mask register for each ASF transaction timeout fault source.
0x238 DSI_TOP__VBUSP_CFG_DSI_0__DSI_REGS_asf_trans_to_fault_status access not given — Status register for transaction timeouts fault. If a fault occurs the revelant status bit will be set to 1. Each bit can be cleared by software writing 1 to each bit.
  [n] ASF_TRANS_TO_FAULT_{n}_STATUS (n=0..3) — Status bits for transaction timeouts faults. (access R/W1TC)
0x240 DSI_TOP__VBUSP_CFG_DSI_0__DSI_REGS_asf_protocol_fault_mask reset 0xF — Control register to mask out ASF Protocol faults from triggering interrupts. On reset, all bits are set to mask out all sources. Clear the corresponding bit to enable the interrupt source. The width of this field is parameterisable and the bit definitions are implementation specific.
  [n] ASF_PROTOCOL_FAULT_{n}_MASK (n=0..3) — Mask register for each ASF protocol fault source.
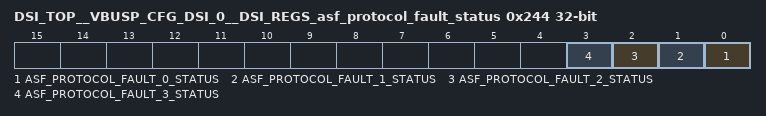
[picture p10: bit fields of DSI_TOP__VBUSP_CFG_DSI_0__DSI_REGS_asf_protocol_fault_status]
0x244 DSI_TOP__VBUSP_CFG_DSI_0__DSI_REGS_asf_protocol_fault_status access not given — Status register for protocol faults. If a fault occurs the revelant status bit will be set to 1. Each bit can be cleared by software writing 1 to each bit
  [n] ASF_PROTOCOL_FAULT_{n}_STATUS (n=0..3) — Status bits for protocol faults. (access R/W1TC)
